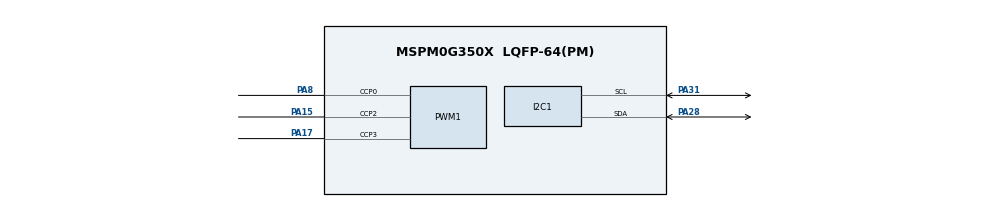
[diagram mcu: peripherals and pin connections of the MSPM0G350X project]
/**
 * @cliArgs --device "MSPM0G350X" --part "Default" --package "LQFP-64(PM)" --product "mspm0_sdk@2.04.00.06"
 * @versions {"tool":"1.22.0+3893"}
 */

/**
 * Import the modules used in this configuration.
 */
const GPIO   = scripting.addModule("/ti/driverlib/GPIO", {}, false);
const GPIO1  = GPIO.addInstance();
const GPIO2  = GPIO.addInstance();
const GPIO3  = GPIO.addInstance();
const I2C    = scripting.addModule("/ti/driverlib/I2C", {}, false);
const I2C1   = I2C.addInstance();
const PWM    = scripting.addModule("/ti/driverlib/PWM", {}, false);
const PWM1   = PWM.addInstance();
const SYSCTL = scripting.addModule("/ti/driverlib/SYSCTL");
const UART   = scripting.addModule("/ti/driverlib/UART", {}, false);
const UART1  = UART.addInstance();
const UART2  = UART.addInstance();

/**
 * Write custom configuration values to the imported modules.
 */
const gate7  = system.clockTree["MFCLKGATE"];
gate7.enable = true;

GPIO1.$name                              = "KEY";
GPIO1.port                               = "PORTA";
GPIO1.associatedPins.create(5);
GPIO1.associatedPins[0].$name            = "KEY_1_Pin";
GPIO1.associatedPins[0].direction        = "INPUT";
GPIO1.associatedPins[0].assignedPin      = "18";
GPIO1.associatedPins[0].internalResistor = "PULL_DOWN";
GPIO1.associatedPins[0].interruptEn      = true;
GPIO1.associatedPins[0].polarity         = "RISE";
GPIO1.associatedPins[1].$name            = "KEY_2_Pin";
GPIO1.associatedPins[1].direction        = "INPUT";
GPIO1.associatedPins[1].assignedPin      = "14";
GPIO1.associatedPins[1].internalResistor = "PULL_DOWN";
GPIO1.associatedPins[1].interruptEn      = true;
GPIO1.associatedPins[1].polarity         = "RISE";
GPIO1.associatedPins[2].$name            = "KEY_3_Pin";
GPIO1.associatedPins[2].direction        = "INPUT";
GPIO1.associatedPins[2].internalResistor = "PULL_DOWN";
GPIO1.associatedPins[2].assignedPin      = "13";
GPIO1.associatedPins[2].interruptEn      = true;
GPIO1.associatedPins[2].polarity         = "RISE";
GPIO1.associatedPins[3].$name            = "KEY_4_Pin";
GPIO1.associatedPins[3].direction        = "INPUT";
GPIO1.associatedPins[3].internalResistor = "PULL_DOWN";
GPIO1.associatedPins[3].assignedPin      = "12";
GPIO1.associatedPins[3].interruptEn      = true;
GPIO1.associatedPins[3].polarity         = "RISE";
GPIO1.associatedPins[4].$name            = "KEY_5_Pin";
GPIO1.associatedPins[4].direction        = "INPUT";
GPIO1.associatedPins[4].assignedPin      = "11";

const Board = scripting.addModule("/ti/driverlib/Board", {}, false);

GPIO2.$name                          = "OLED";
GPIO2.port                           = "PORTA";
GPIO2.associatedPins.create(2);
GPIO2.associatedPins[0].$name        = "SCL";
GPIO2.associatedPins[0].initialValue = "SET";
GPIO2.associatedPins[0].ioStructure  = "OD";
GPIO2.associatedPins[0].assignedPin  = "0";
GPIO2.associatedPins[1].$name        = "SDA";
GPIO2.associatedPins[1].initialValue = "SET";
GPIO2.associatedPins[1].ioStructure  = "OD";
GPIO2.associatedPins[1].assignedPin  = "1";

GPIO3.$name                          = "BEEP";
GPIO3.associatedPins[0].$name        = "beep";
GPIO3.associatedPins[0].assignedPort = "PORTA";
GPIO3.associatedPins[0].assignedPin  = "3";

I2C1.$name                     = "I2C_0";
I2C1.basicEnableController     = true;
I2C1.peripheral.sdaPin.$assign = "PA28";
I2C1.peripheral.sclPin.$assign = "PA31";
I2C1.sdaPinConfig.$name        = "ti_driverlib_gpio_GPIOPinGeneric6";
I2C1.sclPinConfig.$name        = "ti_driverlib_gpio_GPIOPinGeneric7";

PWM1.$name                      = "PWM_0";
PWM1.clockPrescale              = 8;
PWM1.timerStartTimer            = true;
PWM1.ccIndex                    = [0,1,2,3];
PWM1.timerCount                 = 10000;
PWM1.pwmMode                    = "EDGE_ALIGN_UP";
PWM1.peripheral.ccp0Pin.$assign = "PA8";
PWM1.peripheral.ccp2Pin.$assign = "PA15";
PWM1.peripheral.ccp3Pin.$assign = "PA17";
PWM1.PWM_CHANNEL_0.$name        = "ti_driverlib_pwm_PWMTimerCC0";
PWM1.PWM_CHANNEL_1.$name        = "ti_driverlib_pwm_PWMTimerCC1";
PWM1.ccp0PinConfig.$name        = "ti_driverlib_gpio_GPIOPinGeneric0";
PWM1.ccp1PinConfig.$name        = "ti_driverlib_gpio_GPIOPinGeneric1";
PWM1.PWM_CHANNEL_2.$name        = "ti_driverlib_pwm_PWMTimerCC2";
PWM1.PWM_CHANNEL_3.$name        = "ti_driverlib_pwm_PWMTimerCC3";
PWM1.ccp2PinConfig.$name        = "ti_driverlib_gpio_GPIOPinGeneric2";
PWM1.ccp3PinConfig.$name        = "ti_driverlib_gpio_GPIOPinGeneric3";

SYSCTL.forceDefaultClkConfig = true;
SYSCTL.clockTreeEn           = true;

UART1.targetBaudRate                   = 115200;
UART1.uartClkSrc                       = "MFCLK";
UART1.enabledInterrupts                = ["RX"];
UART1.$name                            = "Imu";
UART1.txPinConfig.direction            = scripting.forceWrite("OUTPUT");
UART1.txPinConfig.hideOutputInversion  = scripting.forceWrite(false);
UART1.txPinConfig.onlyInternalResistor = scripting.forceWrite(false);
UART1.txPinConfig.passedPeripheralType = scripting.forceWrite("Digital");
UART1.txPinConfig.$name                = "ti_driverlib_gpio_GPIOPinGeneric8";
UART1.rxPinConfig.hideOutputInversion  = scripting.forceWrite(false);
UART1.rxPinConfig.onlyInternalResistor = scripting.forceWrite(false);
UART1.rxPinConfig.passedPeripheralType = scripting.forceWrite("Digital");
UART1.rxPinConfig.$name                = "ti_driverlib_gpio_GPIOPinGeneric9";

UART2.$name                            = "Debug";
UART2.uartClkSrc                       = "MFCLK";
UART2.targetBaudRate                   = 115200;
UART2.enabledInterrupts                = ["RX"];
UART2.txPinConfig.$name                = "ti_driverlib_gpio_GPIOPinGeneric4";
UART2.txPinConfig.direction            = scripting.forceWrite("OUTPUT");
UART2.txPinConfig.hideOutputInversion  = scripting.forceWrite(false);
UART2.txPinConfig.onlyInternalResistor = scripting.forceWrite(false);
UART2.txPinConfig.passedPeripheralType = scripting.forceWrite("Digital");
UART2.rxPinConfig.$name                = "ti_driverlib_gpio_GPIOPinGeneric5";
UART2.rxPinConfig.hideOutputInversion  = scripting.forceWrite(false);
UART2.rxPinConfig.onlyInternalResistor = scripting.forceWrite(false);
UART2.rxPinConfig.passedPeripheralType = scripting.forceWrite("Digital");

/**
 * Pinmux solution for unlocked pins/peripherals. This ensures that minor changes to the automatic solver in a future
 * version of the tool will not impact the pinmux you originally saw.  These lines can be completely deleted in order to
 * re-solve from scratch.
 */
GPIO1.associatedPins[0].pin.$suggestSolution = "PA18";
GPIO1.associatedPins[1].pin.$suggestSolution = "PA14";
GPIO1.associatedPins[2].pin.$suggestSolution = "PA13";
GPIO1.associatedPins[3].pin.$suggestSolution = "PA12";
GPIO1.associatedPins[4].pin.$suggestSolution = "PA11";
Board.peripheral.$suggestSolution            = "DEBUGSS";
Board.peripheral.swclkPin.$suggestSolution   = "PA20";
Board.peripheral.swdioPin.$suggestSolution   = "PA19";
GPIO2.associatedPins[0].pin.$suggestSolution = "PA0";
GPIO2.associatedPins[1].pin.$suggestSolution = "PA1";
GPIO3.associatedPins[0].pin.$suggestSolution = "PA3";
I2C1.peripheral.$suggestSolution             = "I2C0";
PWM1.peripheral.$suggestSolution             = "TIMA0";
PWM1.peripheral.ccp1Pin.$suggestSolution     = "PA22";
UART1.peripheral.$suggestSolution            = "UART1";
UART1.peripheral.rxPin.$suggestSolution      = "PA9";
UART1.peripheral.txPin.$suggestSolution      = "PB4";
UART2.peripheral.$suggestSolution            = "UART0";
UART2.peripheral.rxPin.$suggestSolution      = "PB1";
UART2.peripheral.txPin.$suggestSolution      = "PA10";
